# neorv32 register map
Vendor: github.com/stnolting/neorv32; Series: RISC-V; File version: 1.13.7
CPU: other r1p0, little endian, MPU, FPU, I-cache, D-cache, ITCM, DTCM, 4 interrupt priority bits
Address unit: 16 bits
Registers are 32-bit, read-write, reset 0x0 unless marked. A register's access mark holds for its fields unless they carry their own. Offsets are from the block's base; [hi:lo] are bit positions.

## WDT — Watchdog timer
Base 0xFFFB0000
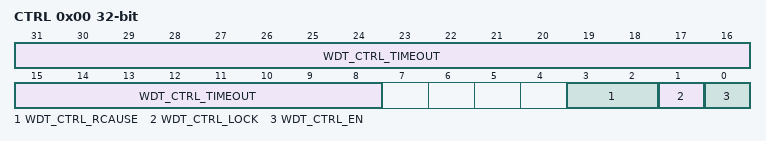
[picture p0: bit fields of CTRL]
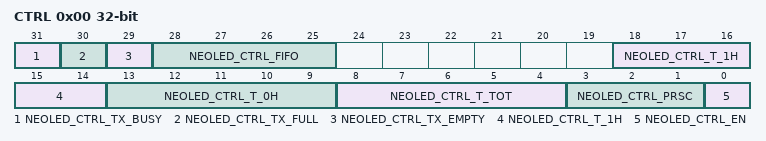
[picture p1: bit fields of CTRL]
0x00 CTRL — Control register
  [31:8] WDT_CTRL_TIMEOUT — Timeout value
  [3:2] WDT_CTRL_RCAUSE ro — Cause of last system reset: 0=external reset, 1=OCD reset, 2=WDT reset, 3=WDT access violation
  [1] WDT_CTRL_LOCK — Lock write access to control register, clears on reset only
  [0] WDT_CTRL_EN — WDT enable flag
0x04 RESET — Watchdog reset register
  [31:0] WDT_RESET wo — Write password to reset/feed the watchdog (0x709D1AB3)

## GPIO — General purpose input/output port
Base 0xFFFC0000
0x00 PORT_IN ro — Parallel input port
0x04 PORT_OUT — Parallel output port
0x08 PORT_DIR — Port direction configuration: 0 = input, 1 = output
0x10 IRQ_TYPE — Interrupt trigger type (level/edge) for each input pin
0x14 IRQ_POLARITY — Interrupt trigger polarity (rising/falling or high/low) for each input pin
0x18 IRQ_ENABLE — Interrupt enable for each input pin
0x1C IRQ_PENDING — Interrupt pending for each input pin; cleared by writing zero

## NEOLED — Smart LED hardware interface
Base 0xFFFD0000
0x00 CTRL — Control register
  [31] NEOLED_CTRL_TX_BUSY ro — busy flag
  [30] NEOLED_CTRL_TX_FULL ro — TX FIFO is full
  [29] NEOLED_CTRL_TX_EMPTY ro — TX FIFO is empty
  [28:25] NEOLED_CTRL_FIFO ro — log2(TX FIFO size)
  [18:14] NEOLED_CTRL_T_1H — pulse-clock ticks per ONE high-time
  [13:9] NEOLED_CTRL_T_0H — pulse-clock ticks per ZERO high-time
  [8:4] NEOLED_CTRL_T_TOT — pulse-clock ticks per total period bit
  [3:1] NEOLED_CTRL_PRSC — Clock prescaler select
  [0] NEOLED_CTRL_EN — NEOLED enable flag
0x04 DATA24 wo — Send 24-bit data
0x08 DATA32 wo — Send 32-bit data
0x0C STROBE wo — Write any value to send STROBE command

## TRACEBUF — Execution Trace Buffer
Base 0xFFF30000
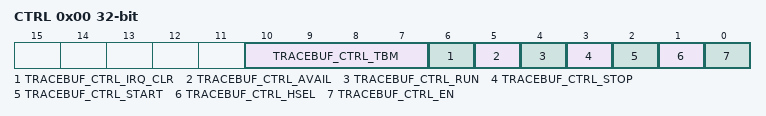
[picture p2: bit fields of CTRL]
0x00 CTRL — Control and status register
  [10:7] TRACEBUF_CTRL_TBM ro — log2 of trace buffer depth
  [6] TRACEBUF_CTRL_IRQ_CLR wo — Clear pending interrupt when writing 1
  [5] TRACEBUF_CTRL_AVAIL ro — Trace data available when set
  [4] TRACEBUF_CTRL_RUN ro — Tracing in progress when set
  [3] TRACEBUF_CTRL_STOP wo — Manually stop tracing, flag always reads as zero
  [2] TRACEBUF_CTRL_START wo — Start tracing, flag always reads as zero
  [1] TRACEBUF_CTRL_HSEL — Hart select for tracing
  [0] TRACEBUF_CTRL_EN — TRACEBUF enable, reset module when 0
0x04 STOP_ADDR — Stop tracing when reaching this address, set to all-zero to disable auto-stopping
0x08 DELTA_SRC ro — Trace data: delta source address + first-packet bit
0x0C DELTA_DST ro read-modifies — Trace data: delta destination address + trap-entry bit

## SMC — Serial Memory Controller
Base 0xFFEF0000
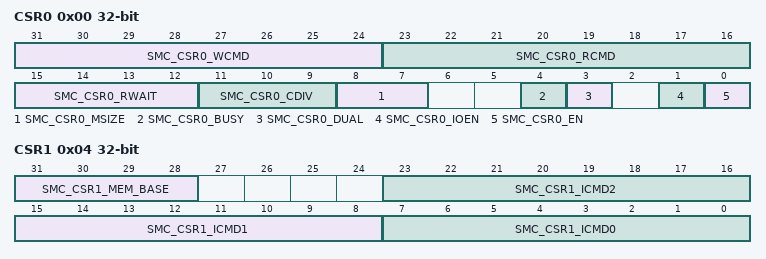
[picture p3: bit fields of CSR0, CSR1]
0x00 CSR0 — Control and status register 0
  [31:24] SMC_CSR0_WCMD — Memory write command
  [23:16] SMC_CSR0_RCMD — Memory read command
  [15:12] SMC_CSR0_RWAIT — Memory read access dummy/wait cycles
  [11:9] SMC_CSR0_CDIV — SPI clock divider
  [8:7] SMC_CSR0_MSIZE — Memory size select
  [4] SMC_CSR0_BUSY ro — Memory operation in progress when set
  [3] SMC_CSR0_DUAL — Enable dual-chip mode
  [1] SMC_CSR0_IOEN — Enable control of SMC IO pins
  [0] SMC_CSR0_EN — SMC enable, reset module when 0
0x04 CSR1 — Control and status register 0
  [31:28] SMC_CSR1_MEM_BASE ro — Memory base address (top 4 bits / 256MB page)
  [23:16] SMC_CSR1_ICMD2 — Initialization command 2
  [15:8] SMC_CSR1_ICMD1 — Initialization command 1
  [7:0] SMC_CSR1_ICMD0 — Initialization command 0

## SYSINFO — System configuration information memory
Base 0xFFFE0000
0x00 CLK — Processor clock speed in Hz
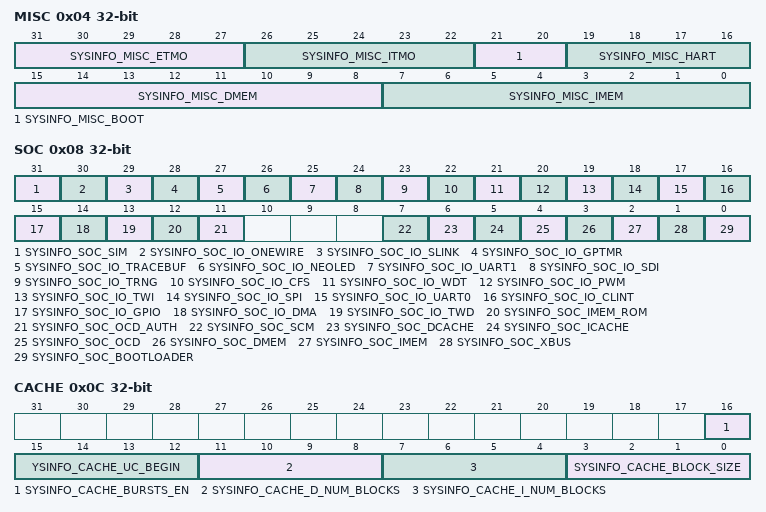
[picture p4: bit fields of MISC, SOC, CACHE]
0x04 MISC ro — Miscellaneous system configurations
  [31:27] SYSINFO_MISC_ETMO — log2(external bus timeout cycles)
  [26:22] SYSINFO_MISC_ITMO — log2(internal bus timeout cycles)
  [21:20] SYSINFO_MISC_BOOT — Boot mode configuration select
  [19:16] SYSINFO_MISC_HART — Number of physical CPU cores
  [15:8] SYSINFO_MISC_DMEM — log2(DMEM size in bytes)
  [7:0] SYSINFO_MISC_IMEM — log2(IMEM size in bytes)
0x08 SOC ro — SoC configuration
  [31] SYSINFO_SOC_SIM — Set if this is a simulation
  [30] SYSINFO_SOC_IO_ONEWIRE — 1-wire interface controller implemented
  [29] SYSINFO_SOC_IO_SLINK — Stream link interface implemented
  [28] SYSINFO_SOC_IO_GPTMR — General purpose timer implemented
  [27] SYSINFO_SOC_IO_TRACEBUF — Execution trace buffer implemented
  [26] SYSINFO_SOC_IO_NEOLED — NeoPixel-compatible smart LED interface implemented
  [25] SYSINFO_SOC_IO_UART1 — Secondary universal asynchronous receiver/transmitter implemented
  [24] SYSINFO_SOC_IO_SDI — Serial data interface implemented
  [23] SYSINFO_SOC_IO_TRNG — True random number generator implemented
  [22] SYSINFO_SOC_IO_CFS — Custom functions subsystem implemented
  [21] SYSINFO_SOC_IO_WDT — Watchdog timer implemented
  [20] SYSINFO_SOC_IO_PWM — Pulse-width modulation unit implemented
  [19] SYSINFO_SOC_IO_TWI — Two-wire interface implemented
  [18] SYSINFO_SOC_IO_SPI — Serial peripheral interface implemented
  [17] SYSINFO_SOC_IO_UART0 — Primary universal asynchronous receiver/transmitter implemented
  [16] SYSINFO_SOC_IO_CLINT — Core local interruptor implemented
  [15] SYSINFO_SOC_IO_GPIO — General purpose input/output port unit implemented
  [14] SYSINFO_SOC_IO_DMA — Direct memory access controller implemented
  [13] SYSINFO_SOC_IO_TWD — Two-wire device implemented
  [12] SYSINFO_SOC_IMEM_ROM — Processor-internal instruction memory implemented as pre-initialized ROM
  [11] SYSINFO_SOC_OCD_AUTH — On-chip debugger authentication implemented
  [7] SYSINFO_SOC_SCM — Serial memory controller implemented
  [6] SYSINFO_SOC_DCACHE — Processor-internal data cache implemented
  [5] SYSINFO_SOC_ICACHE — Processor-internal instruction cache implemented
  [4] SYSINFO_SOC_OCD — On-chip debugger implemented
  [3] SYSINFO_SOC_DMEM — Processor-internal data memory implemented
  [2] SYSINFO_SOC_IMEM — Processor-internal instruction memory implemented
  [1] SYSINFO_SOC_XBUS — External bus interface implemented
  [0] SYSINFO_SOC_BOOTLOADER — Bootloader implemented
0x0C CACHE ro — Cache configuration
  [16] SYSINFO_CACHE_BURSTS_EN — burst transfers enabled
  [15:12] YSINFO_CACHE_UC_BEGIN — start of uncache address space (256MB page)
  [11:8] SYSINFO_CACHE_D_NUM_BLOCKS — log2(Number of d-cache blocks)
  [7:4] SYSINFO_CACHE_I_NUM_BLOCKS — log2(Number of i-cache blocks)
  [3:0] SYSINFO_CACHE_BLOCK_SIZE — log2(Block size in bytes)
